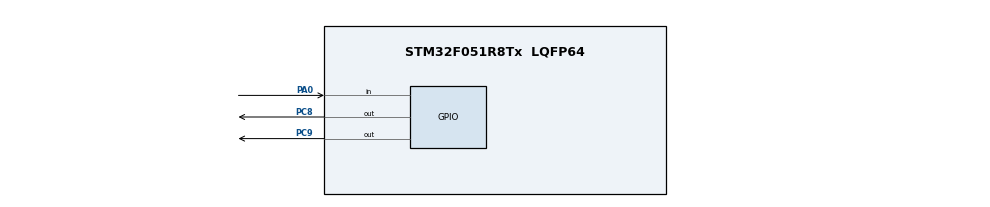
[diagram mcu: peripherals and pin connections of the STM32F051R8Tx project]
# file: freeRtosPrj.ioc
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FREERTOS.Tasks01=defaultTask,0,128,StartDefaultTask,Default,NULL,Static,defaultTaskBuffer,defaultTaskControlBlock;LED1Task,0,128,StartLED1Task,Default,NULL,Static,LED1TaskBuffer,LED1TaskControlBlock;LED2Task,0,128,StartLED2Task,Default,NULL,Static,LED2TaskBuffer,LED2TaskControlBlock
Mcu.Family=STM32F0
Mcu.Name=STM32F051R8Tx
Mcu.Package=LQFP64
NVIC.TIM1_BRK_UP_TRG_COM_IRQn=true\:3\:0\:false\:false\:true\:false\:false\:true\:true
NVIC.TimeBase=TIM1_BRK_UP_TRG_COM_IRQn
NVIC.TimeBaseIP=TIM1
PA0.GPIO_PuPd=GPIO_PULLDOWN
PA0.Signal=GPIO_Input
PA13.Mode=Serial_Wire
PA13.Signal=SYS_SWDIO
PA14.Mode=Serial_Wire
PA14.Signal=SYS_SWCLK
PC8.Signal=GPIO_Output
PC9.Signal=GPIO_Output
ProjectManager.HeapSize=0x200
ProjectManager.StackSize=0x400
ProjectManager.TargetToolchain=STM32CubeIDE
VP_FREERTOS_VS_CMSIS_V1.Mode=CMSIS_V1
VP_SYS_VS_tim1.Mode=TIM1
board=custom

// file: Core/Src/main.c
/* USER CODE BEGIN Header */
/**
  ******************************************************************************
  * @file           : main.c
  * @brief          : Main program body
  ******************************************************************************
  * @attention
  *
  * Copyright (c) 2024 STMicroelectronics.
  * All rights reserved.
  *
  * This software is licensed under terms that can be found in the LICENSE file
  * in the root directory of this software component.
  * If no LICENSE file comes with this software, it is provided AS-IS.
  *
  ******************************************************************************
  */
/* USER CODE END Header */
#include "main.h"
#include "FreeRTOS.h"
#include "task.h"

#include "queue.h"

//#include "stm32f10x.h"
//#include "stm32f10x_gpio.h"
//#include "stm32f10x_rcc.h"
//#include "cmsis_os.h"

//osThreadId defaultTaskHandle;
uint32_t defaultTaskBuffer[ 128 ];
//osStaticThreadDef_t defaultTaskControlBlock;
//osThreadId LED1TaskHandle;
uint32_t LED1TaskBuffer[ 128 ];
//osStaticThreadDef_t LED1TaskControlBlock;
//osThreadId LED2TaskHandle;
uint32_t LED2TaskBuffer[ 128 ];
//osStaticThreadDef_t LED2TaskControlBlock;

void SystemClock_Config(void);
static void MX_GPIO_Init(void);
void StartDefaultTask(void const * argument);
void StartLED1Task(void const * argument);
void StartLED2Task(void const * argument);

/* USER CODE BEGIN 0 */
void LED1Task( void *pvParametrs ) {
	for( ;; ) {
		HAL_GPIO_TogglePin(GPIOC, GPIO_PIN_8);

		HAL_Delay(1000);
	}
	vTaskDelete( NULL );
}

void LED2Task( void *pvParametrs ) {
	for( ;; ) {
		HAL_GPIO_TogglePin(GPIOC, GPIO_PIN_9);

		HAL_Delay(400);
	}
	vTaskDelete( NULL );
}
/* USER CODE END 0 */

int main(void)
{

  /* MCU Configuration--------------------------------------------------------*/

  /* Reset of all peripherals, Initializes the Flash interface and the Systick. */
  HAL_Init();

  /* Configure the system clock */
  SystemClock_Config();

  /* Initialize all configured peripherals */
  MX_GPIO_Init();

  /* Create the thread(s) */
  /* definition and creation of defaultTask */
  //osThreadStaticDef(defaultTask, StartDefaultTask, osPriorityNormal, 0, 128, defaultTaskBuffer, &defaultTaskControlBlock);
  //defaultTaskHandle = osThreadCreate(osThread(defaultTask), NULL);

  /* definition and creation of LED1Task */
 // osThreadStaticDef(LED1Task, StartLED1Task, osPriorityNormal, 0, 128, LED1TaskBuffer, &LED1TaskControlBlock);
  //LED1TaskHandle = osThreadCreate(osThread(LED1Task), NULL);

  /* definition and creation of LED2Task */
 // osThreadStaticDef(LED2Task, StartLED2Task, osPriorityNormal, 0, 128, LED2TaskBuffer, &LED2TaskControlBlock);
//  LED2TaskHandle = osThreadCreate(osThread(LED2Task), NULL);

  /* Start scheduler */
 // osKernelStart();
  /* We should never get here as control is now taken by the scheduler */
  /* Infinite loop */
  /* USER CODE BEGIN WHILE */

   	xTaskCreate( LED1Task, "Task1", 128, NULL, 2, NULL );

  	xTaskCreate( LED2Task, "Task2", 128, NULL, 2, NULL );

   	vTaskStartScheduler();
  while (1)
  {
    /* USER CODE END WHILE */

  }
}

void SystemClock_Config(void)
{
  RCC_OscInitTypeDef RCC_OscInitStruct = {0};
  RCC_ClkInitTypeDef RCC_ClkInitStruct = {0};

  /** Initializes the RCC Oscillators according to the specified parameters
  * in the RCC_OscInitTypeDef structure.
  */
  RCC_OscInitStruct.OscillatorType = RCC_OSCILLATORTYPE_HSI;
  RCC_OscInitStruct.HSIState = RCC_HSI_ON;
  RCC_OscInitStruct.HSICalibrationValue = RCC_HSICALIBRATION_DEFAULT;
  RCC_OscInitStruct.PLL.PLLState = RCC_PLL_NONE;
  if (HAL_RCC_OscConfig(&RCC_OscInitStruct) != HAL_OK)
  {
    Error_Handler();
  }

  /** Initializes the CPU, AHB and APB buses clocks
  */
  RCC_ClkInitStruct.ClockType = RCC_CLOCKTYPE_HCLK|RCC_CLOCKTYPE_SYSCLK
                              |RCC_CLOCKTYPE_PCLK1;
  RCC_ClkInitStruct.SYSCLKSource = RCC_SYSCLKSOURCE_HSI;
  RCC_ClkInitStruct.AHBCLKDivider = RCC_SYSCLK_DIV1;
  RCC_ClkInitStruct.APB1CLKDivider = RCC_HCLK_DIV1;

  if (HAL_RCC_ClockConfig(&RCC_ClkInitStruct, FLASH_LATENCY_0) != HAL_OK)
  {
    Error_Handler();
  }
}

static void MX_GPIO_Init(void)
{
  GPIO_InitTypeDef GPIO_InitStruct = {0};

  /* GPIO Ports Clock Enable */
  __HAL_RCC_GPIOA_CLK_ENABLE();
  __HAL_RCC_GPIOC_CLK_ENABLE();

  /*Configure GPIO pin Output Level */
  HAL_GPIO_WritePin(GPIOC, GPIO_PIN_8|GPIO_PIN_9, GPIO_PIN_RESET);

  /*Configure GPIO pin : PA0 */
  GPIO_InitStruct.Pin = GPIO_PIN_0;
  GPIO_InitStruct.Mode = GPIO_MODE_INPUT;
  GPIO_InitStruct.Pull = GPIO_PULLDOWN;
  HAL_GPIO_Init(GPIOA, &GPIO_InitStruct);

  /*Configure GPIO pins : PC8 PC9 */
  GPIO_InitStruct.Pin = GPIO_PIN_8|GPIO_PIN_9;
  GPIO_InitStruct.Mode = GPIO_MODE_OUTPUT_PP;
  GPIO_InitStruct.Pull = GPIO_NOPULL;
  GPIO_InitStruct.Speed = GPIO_SPEED_FREQ_LOW;
  HAL_GPIO_Init(GPIOC, &GPIO_InitStruct);

}

//void StartDefaultTask(void const * argument)
//{
  /* USER CODE BEGIN 5 */
  /* Infinite loop */
//  for(;;)
//  {
 //   osDelay(1);
//  }
  /* USER CODE END 5 */
//}

void StartLED1Task(void const * argument)
{
  /* USER CODE BEGIN StartLED1Task */
  /* Infinite loop */
  for(;;)
  {
	if( HAL_GPIO_ReadPin(GPIOA, GPIO_PIN_0) ) {
	      HAL_GPIO_TogglePin(GPIOC, GPIO_PIN_8);
	  }

  //  osDelay(200);
  }
  /* USER CODE END StartLED1Task */
}

void StartLED2Task(void const * argument)
{
  /* USER CODE BEGIN StartLED2Task */
  /* Infinite loop */
  for(;;)
  {
	HAL_GPIO_TogglePin(GPIOC, GPIO_PIN_9);
  //  osDelay(1000);
  }
  /* USER CODE END StartLED2Task */
}

void HAL_TIM_PeriodElapsedCallback(TIM_HandleTypeDef *htim)
{
  if (htim->Instance == TIM1) {
    HAL_IncTick();
  }
}

void Error_Handler(void)
{
  __disable_irq();
  while (1)
  {
  }
}
